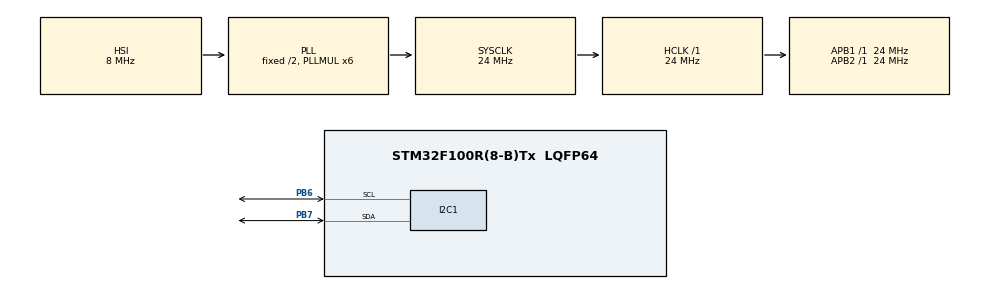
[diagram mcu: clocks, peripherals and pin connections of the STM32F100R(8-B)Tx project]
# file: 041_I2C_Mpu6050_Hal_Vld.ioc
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I2C1.I2C_Mode=I2C_Fast
Mcu.Family=STM32F1
Mcu.Name=STM32F100R(8-B)Tx
Mcu.Package=LQFP64
NVIC.PriorityGroup=NVIC_PRIORITYGROUP_4
PA13.Mode=Serial_Wire
PA13.Signal=SYS_JTMS-SWDIO
PA14.Mode=Serial_Wire
PA14.Signal=SYS_JTCK-SWCLK
PB6.Mode=I2C
PB6.Signal=I2C1_SCL
PB7.Mode=I2C
PB7.Signal=I2C1_SDA
ProjectManager.HeapSize=0x200
ProjectManager.StackSize=0x400
ProjectManager.TargetToolchain=STM32CubeIDE
RCC.AHBFreq_Value=24000000
RCC.APB1Freq_Value=24000000
RCC.APB1TimFreq_Value=24000000
RCC.APB2Freq_Value=24000000
RCC.APB2TimFreq_Value=24000000
RCC.HCLKFreq_Value=24000000
RCC.PLLMUL=RCC_PLL_MUL6
RCC.SYSCLKFreq_VALUE=24000000
RCC.SYSCLKSource=RCC_SYSCLKSOURCE_PLLCLK
board=custom

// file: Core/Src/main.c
/* USER CODE BEGIN Header */
/**
  ******************************************************************************
  * @file           : main.c
  * @brief          : Main program body
  ******************************************************************************
  * @attention
  *
  * Copyright (c) 2024 STMicroelectronics.
  * All rights reserved.
  *
  * This software is licensed under terms that can be found in the LICENSE file
  * in the root directory of this software component.
  * If no LICENSE file comes with this software, it is provided AS-IS.
  *
  ******************************************************************************
  */
/* USER CODE END Header */
#include "main.h"

/* USER CODE BEGIN PM */
#define MPU6050_IC2_SLAVE_ADDRES 0x68

/* USER CODE END PM */

I2C_HandleTypeDef hi2c1;

/* USER CODE BEGIN PV */
uint8_t mydatas[6];
uint16_t i;
int16_t x, y, z;

/* USER CODE END PV */

void SystemClock_Config(void);
static void MX_GPIO_Init(void);
static void MX_I2C1_Init(void);
/* USER CODE BEGIN PFP */

void Mpu6050_Init();
void Mpu6050_Write(uint8_t wRegister, uint8_t numberOfBytes);
void Scan_Slave_Device();
void Mpu6050_Read(uint16_t rRegister, uint16_t numberOfBytes_1 );

/* USER CODE END PFP */

int main(void)
{

  /* MCU Configuration--------------------------------------------------------*/

  /* Reset of all peripherals, Initializes the Flash interface and the Systick. */
  HAL_Init();

  /* Configure the system clock */
  SystemClock_Config();

  /* Initialize all configured peripherals */
  MX_GPIO_Init();
  MX_I2C1_Init();
  /* USER CODE BEGIN 2 */
  Scan_Slave_Device();
  Mpu6050_Init();

  /* USER CODE END 2 */

  /* Infinite loop */
  while (1)
  {

    /* USER CODE BEGIN 3 */
	  Mpu6050_Read(59,6);							// read data accelerometer

	  x = (mydatas[1] << 8) | mydatas[0];
	  y = (mydatas[3] << 8) | mydatas[2];
	  z = (mydatas[5] << 8) | mydatas[4];

  }
  /* USER CODE END 3 */
}

void SystemClock_Config(void)
{
  RCC_OscInitTypeDef RCC_OscInitStruct = {0};
  RCC_ClkInitTypeDef RCC_ClkInitStruct = {0};

  /** Initializes the RCC Oscillators according to the specified parameters
  * in the RCC_OscInitTypeDef structure.
  */
  RCC_OscInitStruct.OscillatorType = RCC_OSCILLATORTYPE_HSI;
  RCC_OscInitStruct.HSIState = RCC_HSI_ON;
  RCC_OscInitStruct.HSICalibrationValue = RCC_HSICALIBRATION_DEFAULT;
  RCC_OscInitStruct.PLL.PLLState = RCC_PLL_ON;
  RCC_OscInitStruct.PLL.PLLSource = RCC_PLLSOURCE_HSI_DIV2;
  RCC_OscInitStruct.PLL.PLLMUL = RCC_PLL_MUL6;
  if (HAL_RCC_OscConfig(&RCC_OscInitStruct) != HAL_OK)
  {
    Error_Handler();
  }

  /** Initializes the CPU, AHB and APB buses clocks
  */
  RCC_ClkInitStruct.ClockType = RCC_CLOCKTYPE_HCLK|RCC_CLOCKTYPE_SYSCLK
                              |RCC_CLOCKTYPE_PCLK1|RCC_CLOCKTYPE_PCLK2;
  RCC_ClkInitStruct.SYSCLKSource = RCC_SYSCLKSOURCE_PLLCLK;
  RCC_ClkInitStruct.AHBCLKDivider = RCC_SYSCLK_DIV1;
  RCC_ClkInitStruct.APB1CLKDivider = RCC_HCLK_DIV1;
  RCC_ClkInitStruct.APB2CLKDivider = RCC_HCLK_DIV1;

  if (HAL_RCC_ClockConfig(&RCC_ClkInitStruct, FLASH_LATENCY_0) != HAL_OK)
  {
    Error_Handler();
  }
}

static void MX_I2C1_Init(void)
{

  hi2c1.Instance = I2C1;
  hi2c1.Init.ClockSpeed = 400000;
  hi2c1.Init.DutyCycle = I2C_DUTYCYCLE_2;
  hi2c1.Init.OwnAddress1 = 0;
  hi2c1.Init.AddressingMode = I2C_ADDRESSINGMODE_7BIT;
  hi2c1.Init.DualAddressMode = I2C_DUALADDRESS_DISABLE;
  hi2c1.Init.OwnAddress2 = 0;
  hi2c1.Init.GeneralCallMode = I2C_GENERALCALL_DISABLE;
  hi2c1.Init.NoStretchMode = I2C_NOSTRETCH_DISABLE;
  if (HAL_I2C_Init(&hi2c1) != HAL_OK)
  {
    Error_Handler();
  }

}

static void MX_GPIO_Init(void)
{

  /* GPIO Ports Clock Enable */
  __HAL_RCC_GPIOA_CLK_ENABLE();
  __HAL_RCC_GPIOB_CLK_ENABLE();

}

/* USER CODE BEGIN 4 */							// <O><0><O><0><O><0><O><0><O><0><O><0><O><0><O><0><O><0><O><0><O><0><O><0><O><0><O><0><O><0><O><0><O><0><O><0><O><0>

void Scan_Slave_Device(){

	for(i=0; i <= 255; i++){

		if(HAL_I2C_IsDeviceReady(&hi2c1,i, 1, 10) == HAL_OK)
			break;
	}
}

void Mpu6050_Read(uint16_t rRegister, uint16_t numberOfBytes_1){

	uint8_t mydatas[6] = {0};
	HAL_I2C_Mem_Read(&hi2c1, 0x68, rRegister, 1, mydatas, numberOfBytes_1,100);
}

void Mpu6050_Write(uint8_t wRegister, uint8_t value){

	uint8_t data[2] = {0};
	data[0] = wRegister;										// buff ilk byte register adresi - 2. si girilecek değer
	data[1] = value;

	HAL_I2C_Master_Transmit(&hi2c1, MPU6050_IC2_SLAVE_ADDRES, data, 1 , 100);

}

void Mpu6050_Init(){

	Mpu6050_Read(0x6b,1);					// read who_am_I register

	Mpu6050_Write(117, 0);					// reset PWR_MGMT_1
	// setup -->

	Mpu6050_Write(107, 0x98);			    //  PWR_MGMT_1: internal osc (8 Mhz) - sleep mode off - reset device
	Mpu6050_Write(28,0x8);					// ACCEL_CONFIG: scale range +-4g
	Mpu6050_Read(107,1);					// read who_am_I register

}

/* USER CODE END 4 */

void Error_Handler(void)
{
  __disable_irq();
  while (1)
  {
  }
}
